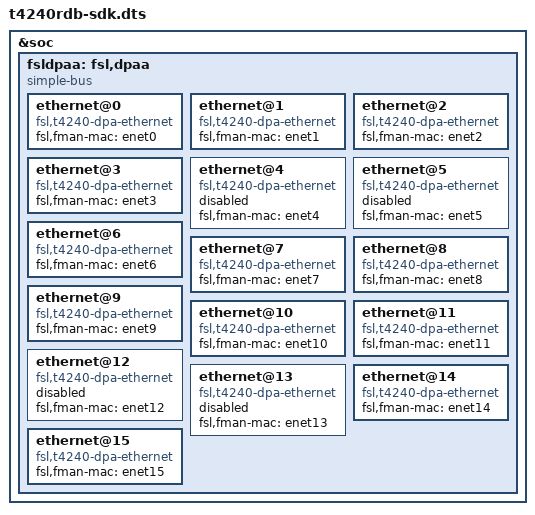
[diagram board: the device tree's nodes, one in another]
/include/ "t4240rdb.dts"

/include/ "qoriq-fman3-0-sdk.dtsi"
/include/ "qoriq-fman3-1-sdk.dtsi"
/include/ "qoriq-bman-portals-sdk.dtsi"
/include/ "qoriq-qman3-portals-sdk.dtsi"
/include/ "qoriq-qman3-ceetm0-32-sdk.dtsi"
/include/ "qoriq-qman3-ceetm1-32-sdk.dtsi"

&soc {
	fsldpaa: fsl,dpaa {
		compatible = "simple-bus", "fsl,dpaa";
		ethernet@0 {
			compatible = "fsl,t4240-dpa-ethernet", "fsl,dpa-ethernet";
			fsl,fman-mac = <&enet0>;
		};
		ethernet@1 {
			compatible = "fsl,t4240-dpa-ethernet", "fsl,dpa-ethernet";
			fsl,fman-mac = <&enet1>;
		};
		ethernet@2 {
			compatible = "fsl,t4240-dpa-ethernet", "fsl,dpa-ethernet";
			fsl,fman-mac = <&enet2>;
		};
		ethernet@3 {
			compatible = "fsl,t4240-dpa-ethernet", "fsl,dpa-ethernet";
			fsl,fman-mac = <&enet3>;
		};
		ethernet@4 {
			compatible = "fsl,t4240-dpa-ethernet", "fsl,dpa-ethernet";
			fsl,fman-mac = <&enet4>;
			status = "disabled";
		};
		ethernet@5 {
			compatible = "fsl,t4240-dpa-ethernet", "fsl,dpa-ethernet";
			fsl,fman-mac = <&enet5>;
			status = "disabled";
		};
		ethernet@6 {
			compatible = "fsl,t4240-dpa-ethernet", "fsl,dpa-ethernet";
			fsl,fman-mac = <&enet6>;
		};
		ethernet@7 {
			compatible = "fsl,t4240-dpa-ethernet", "fsl,dpa-ethernet";
			fsl,fman-mac = <&enet7>;
		};
		ethernet@8 {
			compatible = "fsl,t4240-dpa-ethernet", "fsl,dpa-ethernet";
			fsl,fman-mac = <&enet8>;
		};
		ethernet@9 {
			compatible = "fsl,t4240-dpa-ethernet", "fsl,dpa-ethernet";
			fsl,fman-mac = <&enet9>;
		};
		ethernet@10 {
			compatible = "fsl,t4240-dpa-ethernet", "fsl,dpa-ethernet";
			fsl,fman-mac = <&enet10>;
		};
		ethernet@11 {
			compatible = "fsl,t4240-dpa-ethernet", "fsl,dpa-ethernet";
			fsl,fman-mac = <&enet11>;
		};
		ethernet@12 {
			compatible = "fsl,t4240-dpa-ethernet", "fsl,dpa-ethernet";
			fsl,fman-mac = <&enet12>;
			status = "disabled";
		};
		ethernet@13 {
			compatible = "fsl,t4240-dpa-ethernet", "fsl,dpa-ethernet";
			fsl,fman-mac = <&enet13>;
			status = "disabled";
		};
		ethernet@14 {
			compatible = "fsl,t4240-dpa-ethernet", "fsl,dpa-ethernet";
			fsl,fman-mac = <&enet14>;
		};
		ethernet@15 {
			compatible = "fsl,t4240-dpa-ethernet", "fsl,dpa-ethernet";
			fsl,fman-mac = <&enet15>;
		};
	};
};
